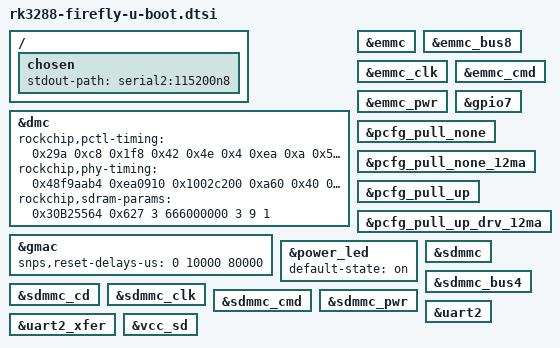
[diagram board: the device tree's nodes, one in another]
// SPDX-License-Identifier: GPL-2.0+
/*
 * Copyright (C) 2019 Rockchip Electronics Co., Ltd
 */

#include "rk3288-u-boot.dtsi"

/ {
	chosen {
		stdout-path = "serial2:115200n8";
	};
};

&dmc {
	rockchip,pctl-timing = <0x29a 0xc8 0x1f8 0x42 0x4e 0x4 0xea 0xa
		0x5 0x0 0xa 0x7 0x19 0x24 0xa 0x7
		0x5 0xa 0x5 0x200 0x5 0x10 0x40 0x0
		0x1 0x7 0x7 0x4 0xc 0x43 0x100 0x0
		0x5 0x0>;
	rockchip,phy-timing = <0x48f9aab4 0xea0910 0x1002c200
		0xa60 0x40 0x10 0x0>;
	/* Add a dummy value to cause of-platdata think this is bytes */
	rockchip,sdram-params = <0x30B25564 0x627 3 666000000 3 9 1>;
};

&emmc {
	bootph-pre-ram;
	bootph-some-ram;
};

&emmc_bus8 {
	bootph-pre-ram;
	bootph-some-ram;
};

&emmc_clk {
	bootph-pre-ram;
	bootph-some-ram;
};

&emmc_cmd {
	bootph-pre-ram;
	bootph-some-ram;
};

&emmc_pwr {
	bootph-pre-ram;
	bootph-some-ram;
};

&gmac {
	snps,reset-delays-us = <0 10000 80000>;
};

&gpio7 {
	/delete-property/ bootph-all;
	bootph-pre-ram;
};

&pcfg_pull_none {
	bootph-all;
};

&pcfg_pull_none_12ma {
	bootph-pre-ram;
	bootph-some-ram;
};

&pcfg_pull_up {
	bootph-all;
};

&pcfg_pull_up_drv_12ma {
	bootph-pre-ram;
	bootph-some-ram;
};

&power_led {
	default-state = "on";
};

&sdmmc {
	bootph-pre-ram;
	bootph-some-ram;
};

&sdmmc_bus4 {
	bootph-pre-ram;
	bootph-some-ram;
};

&sdmmc_cd {
	bootph-pre-ram;
	bootph-some-ram;
};

&sdmmc_clk {
	bootph-pre-ram;
	bootph-some-ram;
};

&sdmmc_cmd {
	bootph-pre-ram;
	bootph-some-ram;
};

&sdmmc_pwr {
	bootph-pre-ram;
};

&uart2 {
	bootph-all;
};

&uart2_xfer {
	bootph-pre-sram;
	bootph-pre-ram;
};

&vcc_sd {
	bootph-pre-ram;
};
